# dm64lc_cslr_tmr_001 register map
Vendor: Texas Instruments
Peripheral module from a debugger description file.
Registers are 32-bit, access not given, reset 0x0 unless marked. A register's access mark holds for its fields unless they carry their own. Offsets are as the file gives them; lines under a group give offsets from that group; [hi:lo] are bit positions; {n}, {i} and the like mark numbered series; 'fields as' and 'values as' point back to an identical list; <NAME> marks a mode.

## TMR — Timer
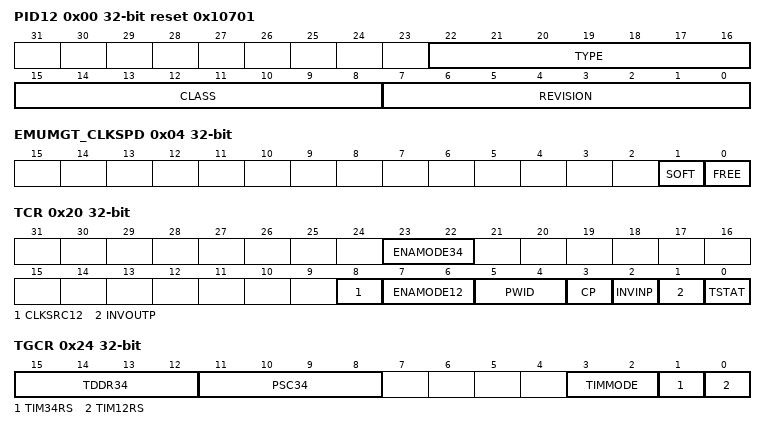
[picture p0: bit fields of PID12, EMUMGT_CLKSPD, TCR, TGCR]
0x00 PID12 reset 0x10701 — Peripheral ID register 12
  [22:16] TYPE ro — Identifies the type of peripheral
  [15:8] CLASS ro — Identifies the class of peripheral
  [7:0] REVISION ro — Identifies the revision level of the timer This value should be 0x01, and be incremented each time the design is revised
0x04 EMUMGT_CLKSPD — Emulation Management/ Clock Speed Register
  [1] SOFT rw — Determines emulation mode functionality of the timer When the FREE bit is cleared, the SOFT bit selects the timer mode 0: The timer stops immediately 1: The timer stops when the counter increments and reaches the value in the timer period register
  [0] FREE rw — Determines emulation mode functionality of the timer When the FREE bit is cleared, the SOFT bit selects the timer mode 0: The Soft bit selects the timer mode 1: The timer runs free regardless of the soft bit
0x10 TIM12 rw — Timer Counter Register 12
  [31:0] TIM12 — TIM12 count bits. This 32-bit value is the current count of the main counter.
0x14 TIM34 rw — Timer Counter Register 34
  [31:0] TIM34 — TIM34 count bits. This 32-bit value is the current count of the main counter.
0x18 PRD12 rw — Timer Period Register 12
  [31:0] PRD12 — PRD12 period bits. This 32-bit value is the number of timer input clock cycles to count.
0x1C PRD34 rw — Timer Period Register 34
  [31:0] PRD34 — PRD34 period bits. This 16-bit value is the number of timer input clock cycles to count.
0x20 TCR — Timer Control Register
  [23:22] ENAMODE34 rw — Enabling mode determines the enabling modes of the timer 00: The timer is disabled (not counting) and maintains current value 01: The timer is enabled one time. The timer stops after the counter reaches the period 10: The timer is enabled continuously, TIMx increments until the timer counter matches the period, resets the timer counter to zero on the cycle after matching and continues 11: Reserved. Note that the TCR34 is applicable only when the timer is configured in unchained dual 32-bit timer mode (TGCR[3:2]=[01])
  [8] CLKSRC12 rw — CLKSRC determines the selected clock source for the timer 0: VBUS clock 1: Timer Input pin
  [7:6] ENAMODE12 rw — Enabling mode determines the enabling modes of the timer 00: The timer is disabled (not counting) and maintains current value 01: The timer is enabled one time. The timer stops after the counter reaches the period 10: The timer is enabled continuously, TIMx increments until the timer counter matches the period, resets the timer counter to zero on the cycle after matching and continues 11: Reserved.
  [5:4] PWID rw — Pulse width Only used in pulse mode (C/P_=0) by the timer controls the timer output 00: TSTATx goes inactive one timer clock cycle after the timer counter reaches the period 01: TSTATx goes inactive two timer clock cycles after the timer counter reaches the period 10: TSTATx goes inactive three timer clock cycles after the timer counter reaches the period 11: TSTATx goes inactive four timer clock cycles after the timer counter reaches the period
  [3] CP rw — Clock/Pulse mode for timer output Not applicable in WD mode (TIMMODE[1:0] = 10) 0: Pulse mode. TSTATx is active one timer clock after the timer counter reaches the timer period. PWID[1:0] determines when it goes inactive 1: Clock mode. TIN/TOUT is a 50% duty cycle signal, it toggles high->low or low->high when timer counter reaches zero
  [2] INVINP rw — Timer input inverter control Only affects operation if CLKSRC = 1 0: Uninverted timer input drives timer 1: Inverted timer input drives timer
  [1] INVOUTP rw — Timer output inverter control 0: Uninverted timer output 1: Inverted timer output
  [0] TSTAT ro — Timer status Value of timer output. TSTATx drives the timer output pin when the pin is used as a timer pin (instead of a GPIO) and maybe inverted by setting INVOUTP = 1
0x24 TGCR — Timer Global Control Register
  [15:12] TDDR34 rw — Timer linear divide-down ratio specifies the timer divide-down ratio for the timer TIM34 When the timer enabled, the TDDR34 increments every timer clock. The TIM34 counter (TIM3/TIM4) increments on the cycle after the TDDR34 matches the PSC34. The TDDR34 resets to zero and continues. When the TIM3/TIM4 matches the PRD3/PRD4, the TIM34 stops if it enabled one time or TIM3/TIM4 reset to zero on the cycle after matching the PRD3/PRD4 and TIM34 continues if the timer enabled continuously
  [11:8] PSC34 rw — TIM34 pre-scalar counter specifies the count for TIM34
  [3:2] TIMMODE rw — TIMMODE determines timer mode 00: The timer is in 64-bit GP timer mode 01: The timer is in dual 32-bit timer, unchained mode 10: The timer is in 64-bit Watchdog timer mode 11: The timer is in dual 32-bit timer, chained mode
  [1] TIM34RS rw — TIM34 reset 0: Timer TIM34 is in reset 1: Timer TIM34 is not in reset. TIM34 can be used as a 32-bit timer.Note that in order for the timer functions properly in 64-bit timer mode both TIM34RS_ and TIM12RS_ must be set to '1'. Changing this bit does not affect the timer if the timer is in the watchdog active state.
  [0] TIM12RS rw — TIM12 reset 0: Timer TIM12 is in reset, TOUT(P) is tri-stated 1: Timer TIM12 is not in reset. TIM12 can be used as a 32-bit timer.Note that in order for the timer functions properly in 64-bit timer mode both TIM34RS_ and TIM12RS_ must be set to '1'. Changing this bit does not affect the timer if the timer is in the watchdog active state
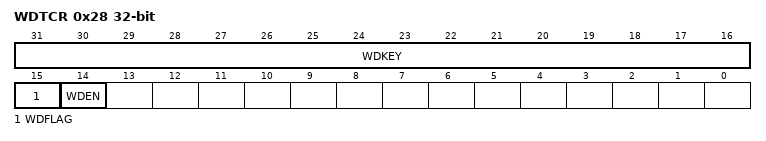
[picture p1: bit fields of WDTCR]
0x28 WDTCR — Watchdog Timer Control Register
  [31:16] WDKEY rw — 16-bit watchdog reset key Only the sequence of an A5C6h followed by a DA7Eh services the watchdog. Not applicable in regular timer mode
  [15] WDFLAG rw — Watchdog flag bit This bit can be cleared by enabling the watchdog timer, by device reset and by being written with '1'. It is set by a watchdog time-out 0: No watchdog timeout occurred 1: Watchdog timeout occurred
  [14] WDEN rw — Watchdog timer enable bit 0: Watchdog disable, watchdog output pin is disconnected from the watchdog timeout event. The timer is in regular timer mode 1: Watchdog enable. TIN/TOUT pin is an output and connected to the watchdog timeout event, can be disabled by watchdog timeout or reset
